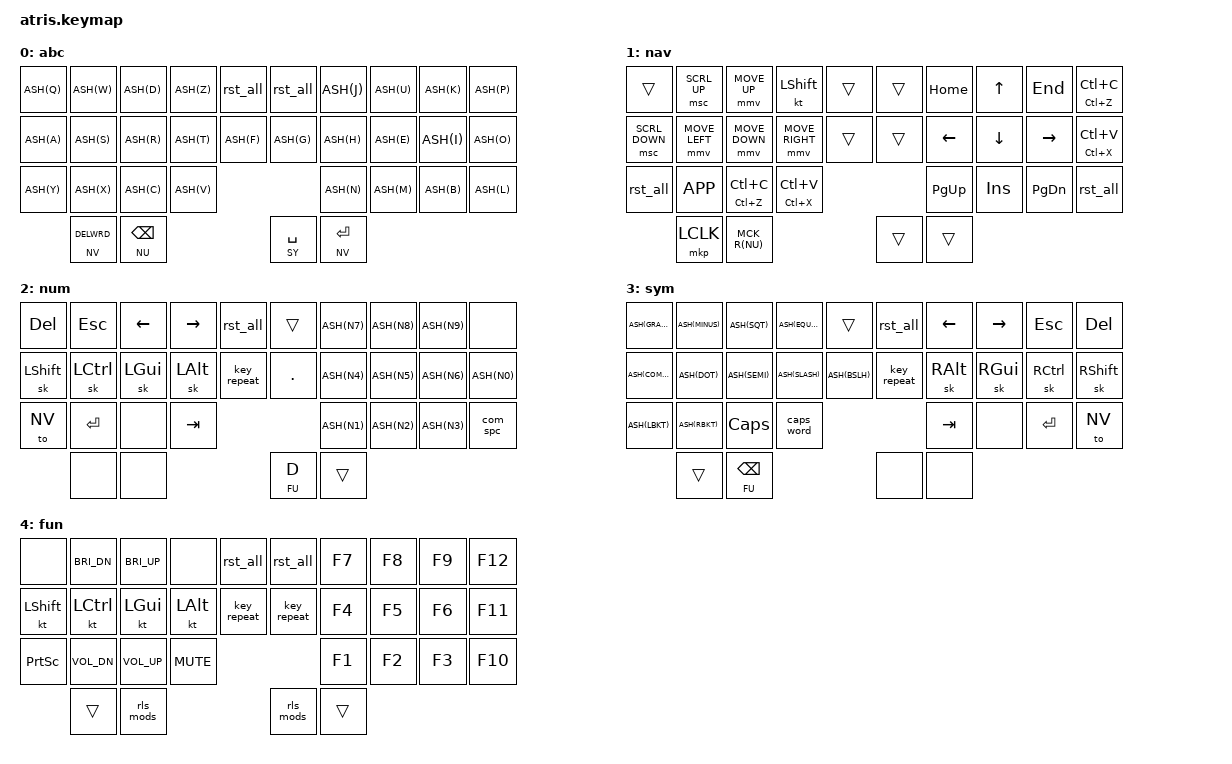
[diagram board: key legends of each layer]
#include <behaviors.dtsi>
#include <dt-bindings/zmk/keys.h>
#include <dt-bindings/zmk/bt.h>

&caps_word { continue-list = <MINUS UNDERSCORE BKSP DEL LEFT RIGHT DOT COMMA SEMI SLASH>; };
&sk { release-after-ms = <3000>; quick-release; ignore-modifiers; };
&sl { release-after-ms = <3000>; };

#define AZ  0
#define NV  1
#define NU  2
#define SY  3
#define FU  4

#define xxxx &none
#define ____ &trans
#define ASH(l) &tkp LS(l) l
#define VX &tkp LC(X) LC(V)
#define CZ &tkp LC(Z) LC(C)
#define DELWRD LC(BKSP)
#define WRD_N RC(RIGHT)
#define WRD_P LC(LEFT)
#define TAB_N RA(RIGHT)
#define TAB_P LA(LEFT)


#define ZMK_MOUSE_DEFAULT_MOVE_VAL 1400  // 600
#define ZMK_MOUSE_DEFAULT_SCRL_VAL 30    // 10

#include <dt-bindings/zmk/mouse.h>
#include <behaviors/mouse_keys.dtsi>

&mmv {
  acceleration-exponent = <1>;      // 1
  time-to-max-speed-ms = <800>;    // 40
  delay-ms = <0>;                   // 0
};

&msc {
  acceleration-exponent = <1>;      // 0
  time-to-max-speed-ms = <40>;    // 500
  delay-ms = <0>;                   // 10
};

#define MMV_U &mmv MOVE_UP
#define MMV_D &mmv MOVE_DOWN
#define MMV_L &mmv MOVE_LEFT
#define MMV_R &mmv MOVE_RIGHT
#define MWH_U &msc SCRL_UP 
#define MWH_D &msc SCRL_DOWN

#define MCK_L &mkp LCLK 
#define MCK_R(l) &mck l RCLK

/ { 
    macros {
        rls_mods: rls_mods { compatible = "zmk,behavior-macro"; label = "ZM_rls_mods"; #binding-cells = <0>; wait-ms = <5>; tap-ms = <15>;
            bindings = <&macro_release &kp LSHFT &kp LCTRL &kp LALT &kp LGUI>; };
        rst_all:  rst_all  { compatible = "zmk,behavior-macro"; label = "ZM_rst_all"; #binding-cells = <0>; wait-ms = <5>; tap-ms = <15>;
            bindings = <&macro_release &kp LSHFT &kp LCTRL &kp LALT &kp LGUI>, <&macro_tap &to 0>; };
        dot_spc:  dot_spc  { compatible = "zmk,behavior-macro"; label = "ZM_dot_spc"; #binding-cells = <0>; wait-ms = <5>; tap-ms = <15>;
            bindings = <&macro_tap &kp DOT &kp SPACE &sk LSHFT>; };
        com_spc:  com_spc  { compatible = "zmk,behavior-macro"; label = "com_spc"; #binding-cells = <0>; wait-ms = <5>; tap-ms = <15>;
            bindings = <&macro_tap &kp COMMA &kp SPACE>; };
    };

    behaviors {
        mk:  moml_kp      { compatible = "zmk,behavior-hold-tap"; label = "MOML_KP";      #binding-cells = <2>; flavor = "tap-preferred"; tapping-term-ms = <200>; bindings = <&mo>, <&kp>; }; 
        mck: moml_mkp     { compatible = "zmk,behavior-hold-tap"; label = "MOML_MKP";     #binding-cells = <2>; flavor = "tap-preferred"; tapping-term-ms = <200>; bindings = <&mo>, <&mkp>; }; 
        mmd: moml_macro   { compatible = "zmk,behavior-hold-tap"; label = "MOML_MACRO";   #binding-cells = <2>; flavor = "tap-preferred"; tapping-term-ms = <200>; bindings = <&mo>, <&dot_spc>; }; 
        tkp: two_kp       { compatible = "zmk,behavior-hold-tap"; label = "TWO_KP";       #binding-cells = <2>; flavor = "tap-preferred"; tapping-term-ms = <175>; bindings = <&kp>, <&kp>; };         
    };
  
    keymap {
        compatible = "zmk,keymap";
        abc {
            bindings = <
                ASH(Q)  ASH(W)  ASH(D)  ASH(Z)  &rst_all   &rst_all  ASH(J)  ASH(U)  ASH(K)  ASH(P)
                ASH(A)  ASH(S)  ASH(R)  ASH(T)  ASH(F)     ASH(G)    ASH(H)  ASH(E)  ASH(I)  ASH(O) 
                ASH(Y)  ASH(X)  ASH(C)  ASH(V)                       ASH(N)  ASH(M)  ASH(B)  ASH(L) 
                           &mk NV DELWRD  &mk NU BKSP      &mk SY SPACE  &mk NV ENTER
            >;  
        };

        nav { 
            bindings = <
                ____   MWH_U  MMV_U  &kt LSHFT  ____     ____  &kp HOME   &kp UP    &kp END    CZ 
                MWH_D  MMV_L  MMV_D  MMV_R      ____     ____  &kp LEFT   &kp DOWN  &kp RIGHT  VX 
                &rst_all  &kp K_APP  CZ  VX                    &kp PG_UP  &kp INS   &kp PG_DN  &rst_all 
                                     MCK_L  MCK_R(NU)    ____  ____ 
            >;
        };

        num {
            bindings = <
                &kp DEL    &kp ESC    &kp LEFT   &kp RIGHT &rst_all     ____     ASH(N7)  ASH(N8)  ASH(N9)  xxxx 
                &sk LSHFT  &sk LCTRL  &sk LGUI   &sk LALT  &key_repeat  &kp DOT  ASH(N4)  ASH(N5)  ASH(N6)  ASH(N0) 
                &to NV     &kp ENTER  xxxx       &kp TAB                         ASH(N1)  ASH(N2)  ASH(N3)  &com_spc 
                                                         xxxx  xxxx     &mmd FU D  ____ 
            >;
        };
 
        sym {
            bindings = <
                ASH(GRAVE)  ASH(MINUS) ASH(SQT)  ASH(EQUAL)  ____        &rst_all     &kp LEFT  &kp RIGHT  &kp ESC    &kp DEL 
                ASH(COMMA)  ASH(DOT)   ASH(SEMI) ASH(SLASH)  ASH(BSLH)   &key_repeat  &sk RALT  &sk RGUI   &sk RCTRL  &sk RSHFT 
                ASH(LBKT)   ASH(RBKT)  &kp CAPS  &caps_word                           &kp TAB   xxxx       &kp ENTER  &to NV 
                                                    ____  &mk FU BKSP    xxxx  xxxx
            >;
        };

        fun {
            bindings = <
                xxxx       &kp C_BRI_DN  &kp C_BRI_UP  xxxx      &rst_all     &rst_all     &kp F7  &kp F8  &kp F9  &kp F12 
                &kt LSHFT  &kt LCTRL     &kt LGUI      &kt LALT  &key_repeat  &key_repeat  &kp F4  &kp F5  &kp F6  &kp F11 
                &kp PSCRN  &kp C_VOL_DN  &kp C_VOL_UP  &kp C_MUTE                          &kp F1  &kp F2  &kp F3  &kp F10 
                                                           ____  &rls_mods    &rls_mods  ____ 
                >;
        };
    };
};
